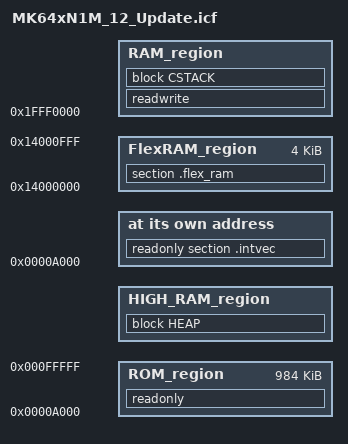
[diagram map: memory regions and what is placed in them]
/*###ICF### Section handled by ICF editor, don't touch! ****/
/*-Editor annotation file-*/
/* IcfEditorFile="$TOOLKIT_DIR$\config\ide\IcfEditor\cortex_v1_0.xml" */
/*-Specials-*/
define symbol __ICFEDIT_intvec_start__ = 0x0000A000;
/*-Memory Regions-*/
define symbol __ICFEDIT_region_ROM_start__ = __ICFEDIT_intvec_start__;
define symbol __ICFEDIT_region_ROM_end__   = 0x000fffff;
define symbol __ICFEDIT_region_RAM_start__ = 0x1fff0000;
define symbol __ICFEDIT_region_RAM_end__   = 0x1fff0000+(66*1024);
/*-Sizes-*/
define symbol __ICFEDIT_size_cstack__ = 4096;
define symbol __ICFEDIT_size_heap__   = 0;
/**** End of ICF editor section. ###ICF###*/

define symbol __region_RAM_CCM_start__      = 0x1fff0000;
define symbol __region_RAM_CCM_end__        = 0x1fffffff;

define symbol __region_RAM2_start__ = 0x20000000;
define symbol __region_RAM2_end__ 	= (0x20000000+((__ICFEDIT_region_RAM_end__)-0x1fffffff));

define symbol __region_RAM3_start__ = ((__region_RAM2_end__)+1);
define symbol __region_RAM3_end__ 	= 0x20030000;

define symbol __region_FlexRAM_start__ 	= 0x14000000;
define symbol __region_FlexRAM_end__   	= 0x14000fff;

define memory mem with size = 4G;
define region ROM_region = mem:[from __ICFEDIT_region_ROM_start__ to __ICFEDIT_region_ROM_end__];
define region HIGH_RAM_region = mem:[from __region_RAM3_start__ to __region_RAM3_end__];
define region RAM_region = mem:[from __region_RAM_CCM_start__ to __region_RAM_CCM_end__] | mem:[from __region_RAM2_start__ to __region_RAM2_end__];
define region FlexRAM_region = mem:[from __region_FlexRAM_start__ to __region_FlexRAM_end__];

define block CSTACK    with alignment = 8, size = __ICFEDIT_size_cstack__   { };
define block HEAP      with alignment = 8, size = __ICFEDIT_size_heap__     { };

initialize by copy { readwrite };
do not initialize  { section .noinit };

keep { section FSymTab };
keep { section VSymTab };

place at address mem:__ICFEDIT_intvec_start__ { readonly section .intvec };

place in ROM_region   { readonly };
place in RAM_region { readwrite, block CSTACK };
place in HIGH_RAM_region { block HEAP };


place in FlexRAM_region   { section .flex_ram };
